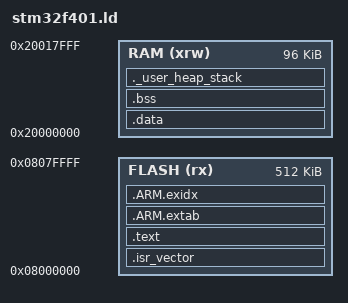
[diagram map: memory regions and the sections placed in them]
/* STM32F401RE linker script */

ENTRY(Reset_Handler)

/* Memories definition */
MEMORY
{
  FLASH (rx)  : ORIGIN = 0x08000000, LENGTH = 512K
  RAM   (xrw) : ORIGIN = 0x20000000, LENGTH = 96K
}

/* Stack/Heap sizes */
_estack = ORIGIN(RAM) + LENGTH(RAM);
_Min_Heap_Size  = 0x400;  /* 1 KB */
_Min_Stack_Size = 0x800;  /* 2 KB */

SECTIONS
{
  /* Vector table */
  .isr_vector :
  {
    . = ALIGN(4);
    KEEP(*(.isr_vector))
    . = ALIGN(4);
  } >FLASH

  .text :
  {
    . = ALIGN(4);
    *(.text*)
    *(.rodata*)
    *(.glue_7)
    *(.glue_7t)
    KEEP(*(.init))
    KEEP(*(.fini))
    . = ALIGN(4);
  } >FLASH

  .ARM.extab :
  {
    *(.ARM.extab* .gnu.linkonce.armextab.*)
  } >FLASH

  .ARM.exidx :
  {
    __exidx_start = .;
    *(.ARM.exidx*)
    __exidx_end = .;
  } >FLASH

  _etext = .;

  .data : AT (_etext)
  {
    _sidata = LOADADDR(.data);
    _sdata = .;
    *(.data*)
    _edata = .;
  } >RAM

  /* Zero-initialized data */
  .bss :
  {
    . = ALIGN(4);
    _sbss = .;
    *(.bss)
    *(.bss*)
    *(COMMON)
    . = ALIGN(4);
    _ebss = .;
  } >RAM

  /* Heap and stack */
  ._user_heap_stack :
  {
    . = ALIGN(8);
    PROVIDE(end = .);
    PROVIDE(_end = .);
    . = . + _Min_Heap_Size;
    . = . + _Min_Stack_Size;
    . = ALIGN(8);
  } >RAM

  /* Remove unused sections */
  /DISCARD/ :
  {
    libc.a ( * )
    libm.a ( * )
    libgcc.a ( * )
  }
}
